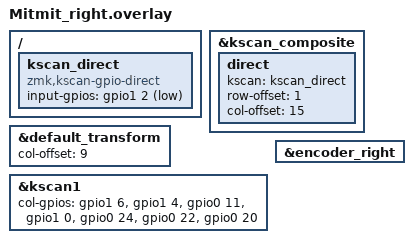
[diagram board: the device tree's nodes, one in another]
#include "Mitmit.dtsi"


/ {
 // Direct GPIO for SW1
	    kscan_direct: kscan_direct {
	        compatible = "zmk,kscan-gpio-direct";
	        input-gpios =                                     // define direct GPIO here...
	            <&gpio1 2 (GPIO_ACTIVE_LOW | GPIO_PULL_UP)>   // Left SW1 (use any free GPIO)
                ;
	        };
  };

&kscan_composite {
        direct {
            kscan = <&kscan_direct>;
	            row-offset = <1>;  // start to count from "default transform col-offset" row 2nd
	            col-offset = <15>;  // position start from "default transform col-offset" col to til the aim 
             };
	  };

&default_transform { 
    col-offset = <9>;
};

&kscan1 {
    col-gpios =
             <&gpio1 6  (GPIO_ACTIVE_HIGH | GPIO_PULL_DOWN)>,  
             <&gpio1 4  (GPIO_ACTIVE_HIGH | GPIO_PULL_DOWN)>,  
             <&gpio0 11 (GPIO_ACTIVE_HIGH | GPIO_PULL_DOWN)>, 
             <&gpio1 0  (GPIO_ACTIVE_HIGH | GPIO_PULL_DOWN)>,  
             <&gpio0 24 (GPIO_ACTIVE_HIGH | GPIO_PULL_DOWN)>, 
             <&gpio0 22 (GPIO_ACTIVE_HIGH | GPIO_PULL_DOWN)>,  
             <&gpio0 20 (GPIO_ACTIVE_HIGH | GPIO_PULL_DOWN)>; 
};

&encoder_right {
    status = "okay";
};

